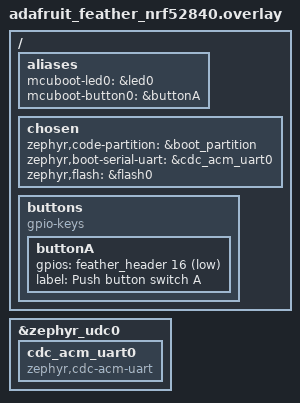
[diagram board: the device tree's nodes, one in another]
// Overlay for nrf52840 board for MCUBoot only!
#include "../../../dts/adafruit_feather_nrf52840_map.dtsi"

/ {
    aliases {
        mcuboot-led0 = &led0;
        mcuboot-button0 = &buttonA;
    };

    chosen {
        zephyr,code-partition = &boot_partition;
        zephyr,boot-serial-uart = &cdc_acm_uart0;
		zephyr,flash = &flash0;
    };

    buttons {
        compatible = "gpio-keys";
        buttonA: buttonA {
			gpios = <&feather_header 16 (GPIO_PULL_UP | GPIO_ACTIVE_LOW)>;
            label = "Push button switch A";
        };
    };
};

&zephyr_udc0 {
	cdc_acm_uart0: cdc_acm_uart0 {
		compatible = "zephyr,cdc-acm-uart";
    };
};
